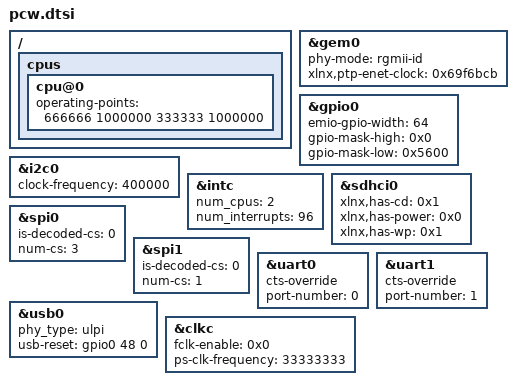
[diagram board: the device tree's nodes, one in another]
/*
 * CAUTION: This file is automatically generated by Xilinx.
 * Version: XSCT 2023.2
 * Today is: Tue Oct 22 21:58:27 2024
 */


/ {
	cpus {
		cpu@0 {
			operating-points = <666666 1000000 333333 1000000>;
		};
	};
};
&gem0 {
	phy-mode = "rgmii-id";
	status = "okay";
	xlnx,ptp-enet-clock = <0x69f6bcb>;
};
&gpio0 {
	emio-gpio-width = <64>;
	gpio-mask-high = <0x0>;
	gpio-mask-low = <0x5600>;
};
&i2c0 {
	clock-frequency = <400000>;
	status = "okay";
};
&intc {
	num_cpus = <2>;
	num_interrupts = <96>;
};
&sdhci0 {
	status = "okay";
	xlnx,has-cd = <0x1>;
	xlnx,has-power = <0x0>;
	xlnx,has-wp = <0x1>;
};
&spi0 {
	is-decoded-cs = <0>;
	num-cs = <3>;
	status = "okay";
};
&spi1 {
	is-decoded-cs = <0>;
	num-cs = <1>;
	status = "okay";
};
&uart0 {
	cts-override ;
	device_type = "serial";
	port-number = <0>;
	status = "okay";
};
&uart1 {
	cts-override ;
	device_type = "serial";
	port-number = <1>;
	status = "okay";
};
&usb0 {
	phy_type = "ulpi";
	status = "okay";
	usb-reset = <&gpio0 48 0>;
};
&clkc {
	fclk-enable = <0x0>;
	ps-clk-frequency = <33333333>;
};
